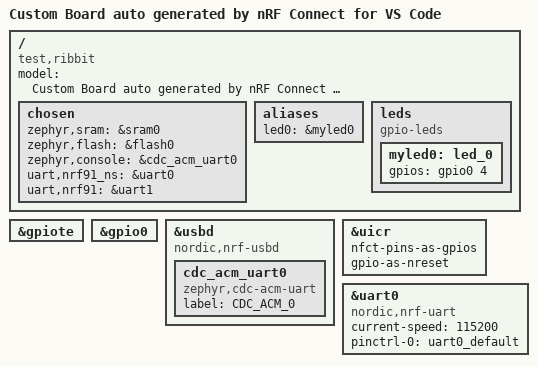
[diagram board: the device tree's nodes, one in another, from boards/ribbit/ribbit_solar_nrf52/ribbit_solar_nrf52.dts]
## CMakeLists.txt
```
cmake_minimum_required(VERSION 3.20.0)
find_package(Zephyr REQUIRED HINTS $ENV{ZEPHYR_BASE})

project(power-hop-interface)

target_sources(app PRIVATE src/main.c)
```

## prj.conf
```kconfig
CONFIG_GPIO=y

# Logging
CONFIG_USB_DEVICE_STACK=y
CONFIG_USB_DEVICE_PRODUCT="Zephyr USB console sample"
CONFIG_USB_DEVICE_PID=0x0004
CONFIG_USB_DEVICE_INITIALIZE_AT_BOOT=n

CONFIG_SERIAL=y
CONFIG_CONSOLE=y

# Using the following option will enable ther Interrupt-driven API 
# The USB stack is not compatible with the Async API, only one type of API will be used per device
CONFIG_UART_CONSOLE=y

# CONFIG_RING_BUFFER=y
CONFIG_UART_0_INTERRUPT_DRIVEN=n
# CONFIG_UART_ASYNC_API=y
# CONFIG_UART_0_ASYNC=y
```

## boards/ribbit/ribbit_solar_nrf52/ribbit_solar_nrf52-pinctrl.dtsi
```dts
&pinctrl {
    uart0_default: uart0_default {
		group1 {
			psels = <NRF_PSEL(UART_TX, 0, 9)>;
		};

		group2 {
			psels = <NRF_PSEL(UART_RX, 0, 10)>;
			bias-pull-up;
		};
	};

	// uart0_sleep: uart0_sleep {
	// 	group1 {
	// 		psels = <NRF_PSEL(UART_TX, 0, 9)>,
    //                 <NRF_PSEL(UART_RX, 0, 10)>;
	// 		low-power-enable;
	// 	};
	// };

    // uart1_default: uart1_default {
	// 	group1 {
	// 		psels = <NRF_PSEL(UART_TX, 0, 15)>;
	// 	};

	// 	group2 {
	// 		psels = <NRF_PSEL(UART_RX, 0, 17)>;
	// 		bias-pull-up;
	// 	};
	// };

	// uart1_sleep: uart1_sleep {
	// 	group1 {
	// 		psels = <NRF_PSEL(UART_TX, 0, 15)>,
    //                 <NRF_PSEL(UART_RX, 0, 17)>;
	// 		low-power-enable;
	// 	};
	// };
};
```

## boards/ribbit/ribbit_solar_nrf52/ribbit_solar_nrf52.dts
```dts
/dts-v1/;
#include <nordic/nrf52833_qdaa.dtsi>
#include "ribbit_solar_nrf52-pinctrl.dtsi"

/ {
	model = "Custom Board auto generated by nRF Connect for VS Code";
	compatible = "test,ribbit";

	chosen {
		zephyr,sram = &sram0;
		zephyr,flash = &flash0;
		zephyr,console = &cdc_acm_uart0;
		// zephyr,nrf91_ns_console = &cdc_acm_uart1;
		uart,nrf91_ns = &uart0;
		// zephyr,nrf91_console = &cdc_acm_uart2;
		uart,nrf91 = &uart1;
	};

	aliases {
		led0 = &myled0;
	};

	leds {
		compatible = "gpio-leds";
		// not actually an LED, but a GPIO that is easily accessible for probing
		myled0: led_0 {
				gpios = <&gpio0 4 GPIO_ACTIVE_HIGH>;
		};
	};
};

&gpiote {
	status = "okay";
};

&gpio0 {
	status = "okay";
};

zephyr_udc0: &usbd {
	compatible = "nordic,nrf-usbd";
	status = "okay";
};

&zephyr_udc0 {
	// nRF52
	cdc_acm_uart0: cdc_acm_uart0 {
		compatible = "zephyr,cdc-acm-uart";
		label = "CDC_ACM_0";
	};

	// // nRF91 ns
	// cdc_acm_uart1: cdc_acm_uart1 {
	// 	compatible = "zephyr,cdc-acm-uart";
	// 	label = "CDC_ACM_1";
	// };

	// // nRF91
	// cdc_acm_uart2: cdc_acm_uart2 {
	// 	compatible = "zephyr,cdc-acm-uart";
	// 	label = "CDC_ACM_2";
	// };
};

&uicr {
    nfct-pins-as-gpios; // Necessary to use uart0 pins
	gpio-as-nreset;
};

&uart0 {
	compatible = "nordic,nrf-uart";
	status = "okay";
	current-speed = <115200>;
	pinctrl-0 = <&uart0_default>;
	// pinctrl-1 = <&uart0_sleep>;
	pinctrl-names = "default"; // , "sleep";
};

// &uart1 {
// 	compatible = "nordic,nrf-uarte";
// 	status = "okay";
// 	current-speed = <115200>;
// 	pinctrl-0 = <&uart1_default>;
// 	pinctrl-1 = <&uart1_sleep>;
// 	pinctrl-names = "default", "sleep";
// };
```

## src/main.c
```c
/*
 * Copyright (c) 2016 Intel Corporation
 *
 * SPDX-License-Identifier: Apache-2.0
 */

 #include <stdio.h>
 #include <zephyr/kernel.h>
 #include <zephyr/sys/printk.h>
 
 #include <zephyr/usb/usb_device.h>
 #include <zephyr/drivers/uart.h>
 #include <zephyr/drivers/gpio.h>
   
 BUILD_ASSERT(DT_NODE_HAS_COMPAT(DT_CHOSEN(zephyr_console), zephyr_cdc_acm_uart),
              "Console device is not ACM CDC UART device");
 
#define DEV_CONSOLE DEVICE_DT_GET(DT_CHOSEN(zephyr_console))
#define DEV_OTHER   DEVICE_DT_GET(DT_CHOSEN(uart_nrf91_ns))	

const struct device *uart = DEV_OTHER;
const struct device *console = DEV_CONSOLE;

static uint8_t rx_buf[128] = {0};

static void uart_cb(const struct device *dev, struct uart_event *evt, void *ctx)
{
	switch (evt->type) {
	case UART_RX_RDY:
		printk("%c", evt->data.rx.buf[evt->data.rx.offset]);
		break;
	case UART_RX_DISABLED:
		uart_rx_enable(dev, rx_buf, sizeof(rx_buf), 100);
		break;

	default:
		break;
	}
}

 int main(void)
 {
	if (usb_enable(NULL)) {
		return 0;
	}

	printk("Hello World! %s\n", CONFIG_ARCH);

	// int err = uart_callback_set(uart, uart_cb, NULL);
	// if (err) {
	// 	printk("ERROR when setting callback %d\n", err);
	// 	return err;
	// }

	// uart_rx_enable(uart, rx_buf, sizeof(rx_buf), 100);
	unsigned char c;
	int ret;
	while (1) {
		ret = uart_poll_in(uart, &c);
		if (ret < -1) {
			printk("uart errored out\n");
			break;
		} else if (ret == 0) {
			printk("%c", c);
		}

		ret = uart_poll_in(console, &c);
		if (ret < -1) {
			printk("uart errored out\n");
			break;
		} else if (ret == 0) {
			uart_poll_out(uart, c);
		}		
	}

	return 0;
 }
```
